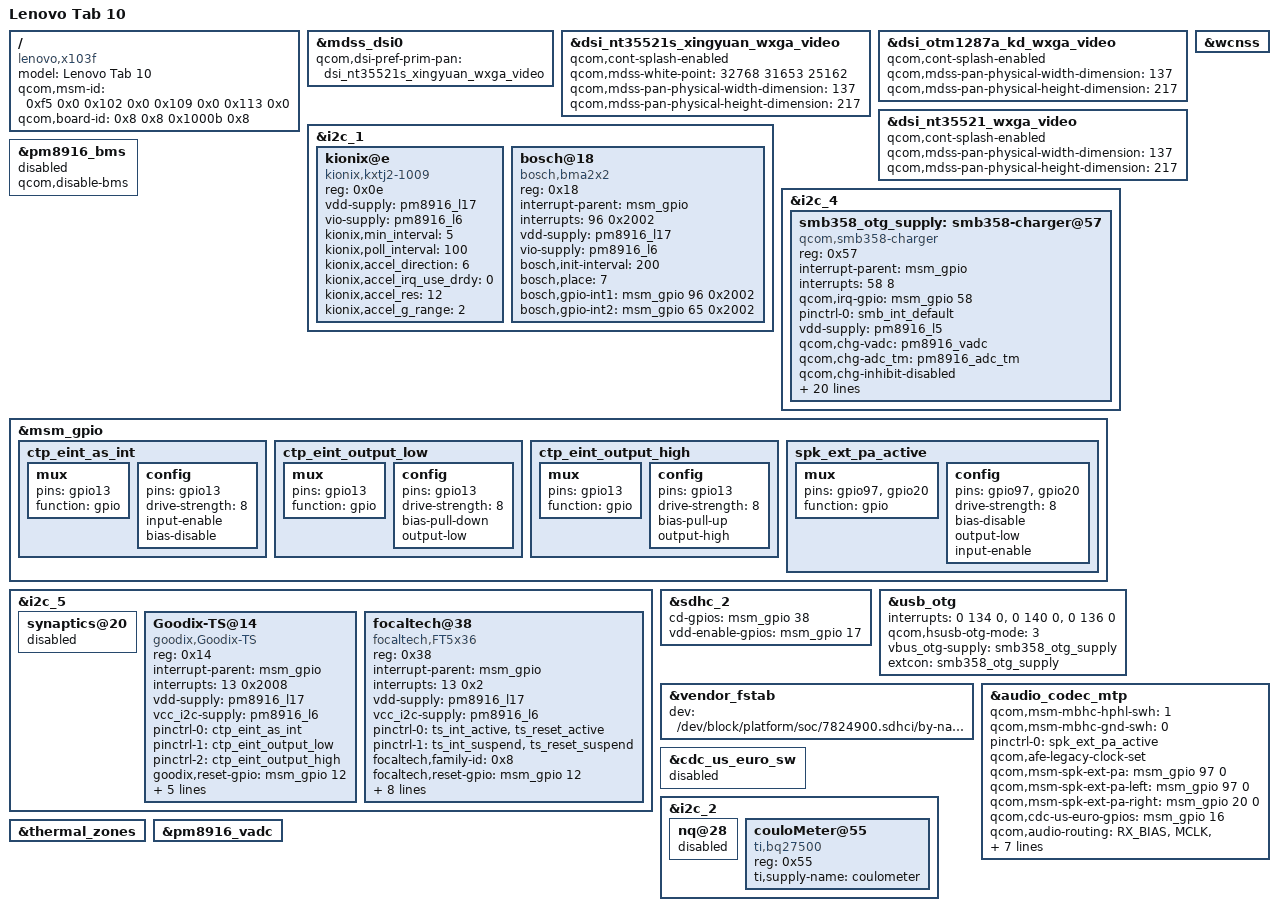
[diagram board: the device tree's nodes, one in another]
/* Copyright (c) 2014-2015, The Linux Foundation. All rights reserved.
 *
 * This program is free software; you can redistribute it and/or modify
 * it under the terms of the GNU General Public License version 2 and
 * only version 2 as published by the Free Software Foundation.
 *
 * This program is distributed in the hope that it will be useful,
 * but WITHOUT ANY WARRANTY; without even the implied warranty of
 * MERCHANTABILITY or FITNESS FOR A PARTICULAR PURPOSE.  See the
 * GNU General Public License for more details.
 */

/dts-v1/;

#include "msm8909-mtp.dtsi"
#include "8909-pm8916.dtsi"
#include "msm8909-pm8916-mtp.dtsi"
#include "apq8009-memory.dtsi"
#include "dsi-panel-nt35521s-xingyuan-wxga-video.dtsi"
#include "dsi-panel-otm1287a-kd-wxga-video.dtsi"
#include "dsi-panel-nt35521-wxga-video.dtsi"
#include "msm8909-x103f-camera.dtsi"

/ {
	model = "Lenovo Tab 10";
	compatible = "lenovo,x103f", "qcom,msm8009-mtp",
			"qcom,msm8909", "qcom,mtp";
	qcom,msm-id = <0xf5 0x0 0x102 0x0 0x109 0x0 0x113 0x0>;
	qcom,board-id = <0x8 0x8 0x1000b 0x8>;
};

&mdss_dsi0 {
	qcom,dsi-pref-prim-pan = <&dsi_nt35521s_xingyuan_wxga_video>;
};

&dsi_nt35521s_xingyuan_wxga_video {
	qcom,cont-splash-enabled;

	qcom,mdss-white-point = <32768 31653 25162>;

	qcom,mdss-pan-physical-width-dimension = <137>;
	qcom,mdss-pan-physical-height-dimension = <217>;
};

&dsi_otm1287a_kd_wxga_video {
	qcom,cont-splash-enabled;
	qcom,mdss-pan-physical-width-dimension = <137>;
	qcom,mdss-pan-physical-height-dimension = <217>;
};

&dsi_nt35521_wxga_video {
	qcom,cont-splash-enabled;
	qcom,mdss-pan-physical-width-dimension = <137>;
	qcom,mdss-pan-physical-height-dimension = <217>;
};

&i2c_1 {
	status = "okay";

	kionix@e {
		compatible = "kionix,kxtj2-1009";
		reg = <0x0e>;
		vdd-supply = <&pm8916_l17>;
		vio-supply = <&pm8916_l6>;
		kionix,min_interval = <5>;
		kionix,poll_interval = <100>;

		kionix,accel_direction = <6>;
		kionix,accel_irq_use_drdy = <0>;
		kionix,accel_res = <12>;
		kionix,accel_g_range = <2>;
	};

	bosch@18 {
		compatible = "bosch,bma2x2";
		reg = <0x18>;
		interrupt-parent = <&msm_gpio>;
		interrupts = <96 0x2002>;
		vdd-supply = <&pm8916_l17>;
		vio-supply = <&pm8916_l6>;
		bosch,init-interval = <200>;
		bosch,place = <7>;
		bosch,gpio-int1 = <&msm_gpio 96 0x2002>;
		bosch,gpio-int2 = <&msm_gpio 65 0x2002>;
	};
};

&i2c_4 {
	status = "okay";

	smb358_otg_supply: smb358-charger@57 {
		compatible = "qcom,smb358-charger";
		reg = <0x57>;
		interrupt-parent = <&msm_gpio>;
		interrupts = <58 8>;
		qcom,irq-gpio = <&msm_gpio 58 0x2008>;
		pinctrl-names = "default";
		pinctrl-0 = <&smb_int_default>;
		vdd-supply = <&pm8916_l5>;
		qcom,chg-vadc = <&pm8916_vadc>;
		qcom,chg-adc_tm = <&pm8916_adc_tm>;
		qcom,chg-inhibit-disabled;
		qcom,float-voltage-mv = <4350>;
		qcom,iterm-ma = <200>;
		qcom,recharge-thresh-mv = <100>;
		qcom,recharge-mv = <100>;
		qcom,thermal-mitigation = <1500 700 600 0>;
		qcom,fg-auto-recharge-soc = <98>;

		qcom,bms-psy-name = "coulometer";
		regulator-name = "smb358_otg_vreg";
		qcom,cold-bat-decidegc = <0>;
		qcom,cool-bat-decidegc = <150>;
		qcom,warm-bat-decidegc = <450>;
		qcom,hot-bat-decidegc = <500>;
		qcom,bat-present-decidegc = <400>;
		qcom,cool-bat-ma = <1300>;
		qcom,warm-bat-ma = <1300>;
		qcom,fastchg-current-max-ma = <2000>;

		qcom,dcp-input-current-ma = <2000>;
		qcom,cool-bat-mv = <4350>;
		qcom,warm-bat-mv = <4100>;
		qcom,soc-delay-worker-time = <15000>;
	};
};

&pm8916_bms {
	status = "disabled";
	qcom,disable-bms;
};

&msm_gpio {
	ctp_eint_as_int: ctp_eint_as_int {
		mux {
			pins = "gpio13";
			function = "gpio";
		};
		config {
			pins = "gpio13";
			drive-strength = <8>;
			input-enable;
			bias-disable;
		};
	};

	ctp_eint_output_low: ctp_eint_output_low {
		mux {
			pins = "gpio13";
			function = "gpio";
		};
		config {
			pins = "gpio13";
			drive-strength = <8>;
			bias-pull-down;
			output-low;
		};
	};

	ctp_eint_output_high: ctp_eint_output_high {
		mux {
			pins = "gpio13";
			function = "gpio";
		};
		config {
			pins = "gpio13";
			drive-strength = <8>;
			bias-pull-up;
			output-high;
		};
	};

	spk_ext_pa_active: spk_ext_pa_active {
		mux {
			pins = "gpio97", "gpio20";
			function = "gpio";
		};
		config {
			pins = "gpio97", "gpio20";
			drive-strength = <8>;
			bias-disable;
			output-low;
			input-enable;
		};
	};
};

&i2c_5 {
	status = "okay";

	synaptics@20 {
		status = "disabled";
	};

	Goodix-TS@14 {
		compatible = "goodix,Goodix-TS";
		reg = <0x14>;
		interrupt-parent = <&msm_gpio>;
		interrupts = <13 0x2008>;
		vdd-supply = <&pm8916_l17>;
		vcc_i2c-supply = <&pm8916_l6>;
		pinctrl-names = "eint_as_int", "eint_output_low",
				"eint_output_high";
		pinctrl-0 = <&ctp_eint_as_int>;
		pinctrl-1 = <&ctp_eint_output_low>;
		pinctrl-2 = <&ctp_eint_output_high>;
		goodix,reset-gpio = <&msm_gpio 12 0x00>;
		goodix,display-coords = <0 0 1280 800>;
		goodix,panel-coords = <0 0 1280 800>;
		goodix,irq-gpio = <&msm_gpio 13 0x00>;
		goodix,button-map = <158 139 172>;
		goodix,i2c-pull-up;
		status = "ok";
	};

	focaltech@38 {
		compatible = "focaltech,FT5x36";
		reg = <0x38>;
		interrupt-parent = <&msm_gpio>;
		interrupts = <13 0x2>;
		vdd-supply = <&pm8916_l17>;
		vcc_i2c-supply = <&pm8916_l6>;
		pinctrl-names = "pmx_ts_active", "pmx_ts_suspend";
		pinctrl-0 = <&ts_int_active &ts_reset_active>;
		pinctrl-1 = <&ts_int_suspend &ts_reset_suspend>;
		focaltech,family-id = <0x8>;
		focaltech,reset-gpio = <&msm_gpio 12 0x0>;
		focaltech,irq-gpio = <&msm_gpio 13 0x0>;
		focaltech,max_touch_point = <10>;
		focaltech,display-coords = <0 0 800 1280>;
		focaltech,panel-coords = <0 0 800 1280>;
		focaltech,button-map = <139 172 158>;
		focaltech,no-force-update;
		focaltech,i2c-pull-up;
		focaltech,auto_clb;
	};
};

&wcnss {
	status = "okay";
};

&sdhc_2 {
	cd-gpios = <&msm_gpio 38 0x0>;
	vdd-enable-gpios = <&msm_gpio 17 0x0>;
};

&usb_otg {
	interrupts = <0 134 0>, <0 140 0>, <0 136 0>;
	interrupt-names = "core_irq", "async_irq", "phy_irq";
	qcom,hsusb-otg-mode = <3>;
	vbus_otg-supply = <&smb358_otg_supply>;
	extcon = <&smb358_otg_supply>;
};

&vendor_fstab {
	dev = "/dev/block/platform/soc/7824900.sdhci/by-name/cache";
};

&audio_codec_mtp {
	qcom,msm-mbhc-hphl-swh = <1>;
	qcom,msm-mbhc-gnd-swh = <0>;
	pinctrl-names = "default";
	pinctrl-0 = <&spk_ext_pa_active>;

	qcom,afe-legacy-clock-set;

	qcom,msm-spk-ext-pa = <&msm_gpio 97 0>;
	qcom,msm-spk-ext-pa-left = <&msm_gpio 97 0>;
	qcom,msm-spk-ext-pa-right = <&msm_gpio 20 0>;

	qcom,cdc-us-euro-gpios = <&msm_gpio 16 0>;
	/delete-property/ qcom,cdc-us-eu-gpios;

	/delete-property/ qcom,msm-micbias1-ext-cap;
	qcom,audio-routing =
		"RX_BIAS", "MCLK",
		"SPK_RX_BIAS", "MCLK",
		"INT_LDO_H", "MCLK",
		"MIC BIAS Internal1", "Handset Mic",
		"MIC BIAS Internal2", "Headset Mic",
		"MIC BIAS Internal3", "Secondary Mic",
		"AMIC1", "MIC BIAS Internal1",
		"AMIC2", "MIC BIAS Internal2",
		"AMIC3", "MIC BIAS Internal3";
};

&cdc_us_euro_sw {
	status = "disabled";
};

&i2c_2 {
	nq@28 {
		status = "disabled";
	};

	couloMeter@55 {
		compatible = "ti,bq27500";
		reg = <0x55>;
		ti,supply-name = "coulometer";
	};
};

&thermal_zones {
	/delete-node/ pa-therm0-adc;
};

&pm8916_vadc {
	/delete-node/ chan@36;
};
